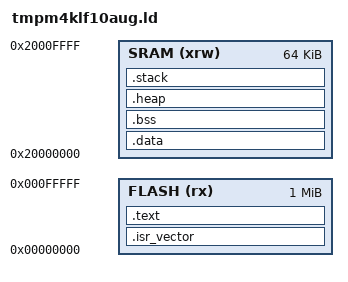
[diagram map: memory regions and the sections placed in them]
/*
******************************************************************************
**
** @file        : tmpm4klf10aug.ld
** @author      : Strahinja Jacimovic (MikroE)
** @brief       : Linker script for tmpm4klf10aug Device
**                1024Kbytes FLASH
**                64Kbytes RAM
*
**                Set heap size, stack size and stack location according
**                to application requirements.
**
**                Set memory bank area and size if external memory is used
**
**  Target      : TOSHIBA TMPM4KLF10AUG
**
**  Distribution: The file is distributed as is, without any warranty
**                of any kind.
**
******************************************************************************
** @attention
**
** Copyright (c) ${COPYRIGHT_YEAR_MIKROE} MikroElektronika.
** All rights reserved.
**
** This software is licensed under terms that can be found in the LICENSE file
** in the root directory of this software component.
** If no LICENSE file comes with this software, it is provided AS-IS.
**
******************************************************************************
*/

/* Entry Point */
ENTRY(Reset_Handler)

_Min_Heap_Size = 0x200; /* required amount of heap */
_Min_Stack_Size = 0x400; /* required amount of stack */

/* Memories definition */
MEMORY
{
  SRAM    (xrw)    : ORIGIN = 0x20000000,   LENGTH = 64K
  FLASH    (rx)    : ORIGIN = 0x0000000,   LENGTH = 1024K
}

_estack = ORIGIN(SRAM) + LENGTH(SRAM);    /* end of SRAM */

SECTIONS
{
    .isr_vector :
    {
        . = ALIGN(4);
        KEEP(*(.isr_vector))
        . = ALIGN(4);
    } > FLASH

    .text :
    {
        . = ALIGN(4);
        *(.text)           /* .text sections (code) */
        *(.text*)          /* .text* sections (code) */
        *(.glue_7)         /* glue arm to thumb code */
        *(.glue_7t)        /* glue thumb to arm code */
        *(.eh_frame)

        KEEP (*(.init))
        KEEP (*(.fini))
        . = ALIGN(4);
        _etext = .;
    } > FLASH

    .data : AT(ADDR(.text) + SIZEOF(.text))
    {
        . = ALIGN (4);
        _data = .;
        __data_load__ = LOADADDR (.data);
        __data_start__ = _data;
        *(vtable)
        *(.data*)
        *(.RamFunc)        /* .RamFunc sections */
        *(.RamFunc*)       /* .RamFunc* sections */
        . = ALIGN (4);
        _edata = .;
        __data_end__ = _edata;
    } > SRAM

    . = ALIGN(4);
    .bss :
    {
        _bss = .;
        __bss_start__ = _bss;
        *(.bss*)
        *(COMMON)
        . = ALIGN(4);
        _ebss = .;
        __bss_end__ = _ebss;
    } > SRAM

    .heap : {
        __heap_start__ = .;
        end = __heap_start__;
        _end = end;
        __end = end;
        KEEP(*(.heap))
        __heap_end__ = .;
        __HeapLimit = __heap_end__;
    } > SRAM

    .stack : ALIGN(0x8) {
        . = ALIGN(8);
        PROVIDE ( end = . );
        PROVIDE ( _end = . );
        . = . + _Min_Heap_Size;
        . = . + _Min_Stack_Size;
        . = ALIGN(8);
    } > SRAM

    /* Remove information from the standard libraries */
    /DISCARD/ :
    {
        libc.a ( * )
        libm.a ( * )
        libgcc.a ( * )
    }

    .ARM.attributes 0 : { *(.ARM.attributes) }
}
